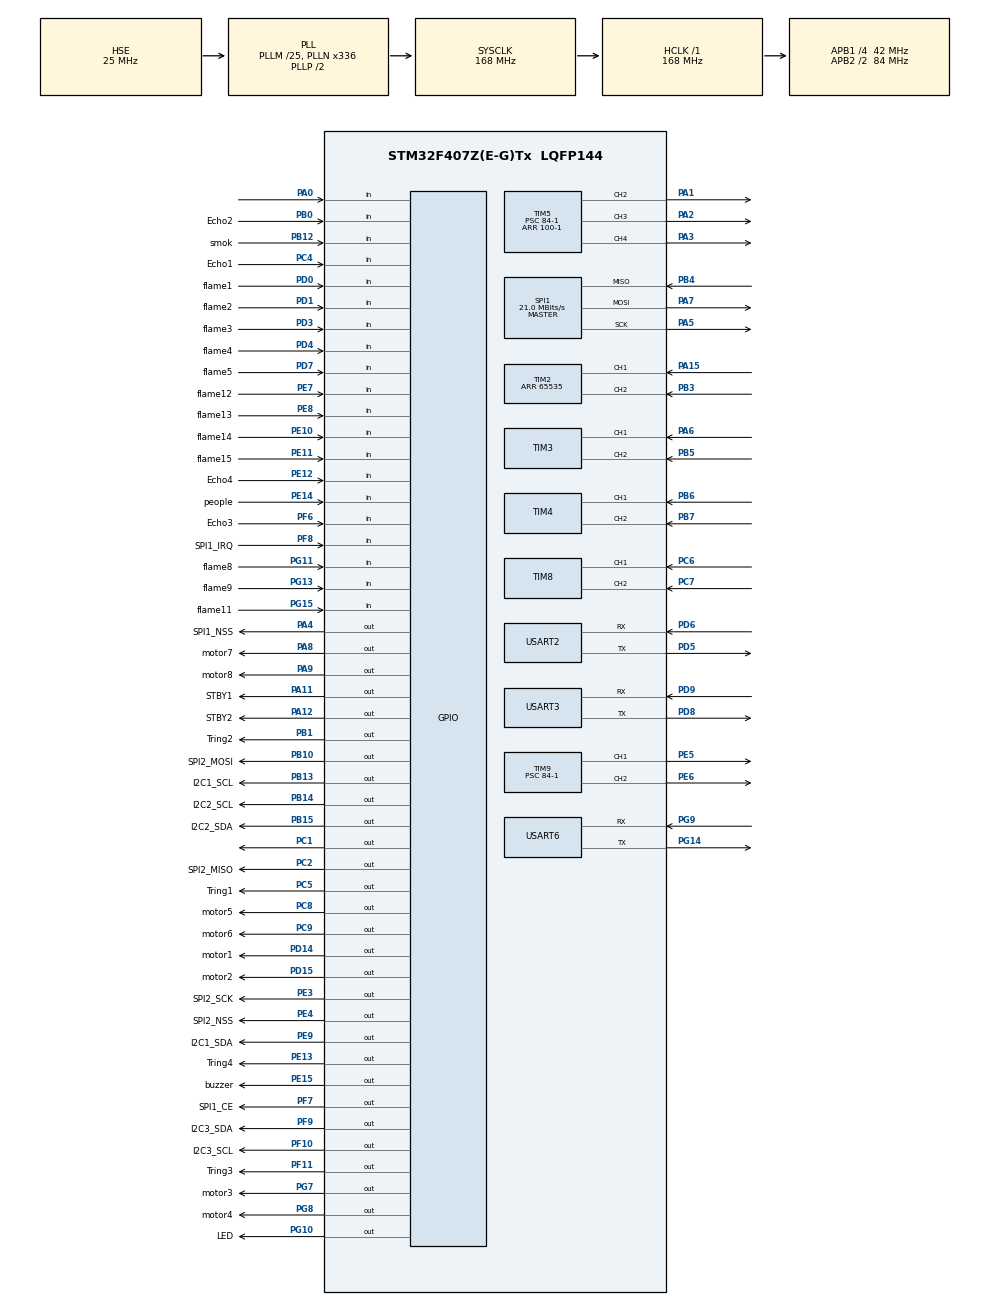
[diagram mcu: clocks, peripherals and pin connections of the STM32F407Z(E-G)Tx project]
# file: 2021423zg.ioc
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Dma.Request0=USART2_RX
Dma.Request1=SPI1_TX
Dma.Request2=USART6_RX
Dma.SPI1_TX.1.Direction=DMA_MEMORY_TO_PERIPH
Dma.SPI1_TX.1.FIFOMode=DMA_FIFOMODE_DISABLE
Dma.SPI1_TX.1.Instance=DMA2_Stream3
Dma.SPI1_TX.1.MemDataAlignment=DMA_MDATAALIGN_BYTE
Dma.SPI1_TX.1.MemInc=DMA_MINC_ENABLE
Dma.SPI1_TX.1.Mode=DMA_CIRCULAR
Dma.SPI1_TX.1.PeriphDataAlignment=DMA_PDATAALIGN_BYTE
Dma.SPI1_TX.1.PeriphInc=DMA_PINC_DISABLE
Dma.SPI1_TX.1.Priority=DMA_PRIORITY_LOW
Dma.USART2_RX.0.Direction=DMA_PERIPH_TO_MEMORY
Dma.USART2_RX.0.FIFOMode=DMA_FIFOMODE_DISABLE
Dma.USART2_RX.0.Instance=DMA1_Stream5
Dma.USART2_RX.0.MemDataAlignment=DMA_MDATAALIGN_BYTE
Dma.USART2_RX.0.MemInc=DMA_MINC_ENABLE
Dma.USART2_RX.0.Mode=DMA_CIRCULAR
Dma.USART2_RX.0.PeriphDataAlignment=DMA_PDATAALIGN_BYTE
Dma.USART2_RX.0.PeriphInc=DMA_PINC_DISABLE
Dma.USART2_RX.0.Priority=DMA_PRIORITY_LOW
Dma.USART6_RX.2.Direction=DMA_PERIPH_TO_MEMORY
Dma.USART6_RX.2.FIFOMode=DMA_FIFOMODE_DISABLE
Dma.USART6_RX.2.Instance=DMA2_Stream1
Dma.USART6_RX.2.MemDataAlignment=DMA_MDATAALIGN_BYTE
Dma.USART6_RX.2.MemInc=DMA_MINC_ENABLE
Dma.USART6_RX.2.Mode=DMA_CIRCULAR
Dma.USART6_RX.2.PeriphDataAlignment=DMA_PDATAALIGN_BYTE
Dma.USART6_RX.2.PeriphInc=DMA_PINC_DISABLE
Dma.USART6_RX.2.Priority=DMA_PRIORITY_LOW
Mcu.Family=STM32F4
Mcu.Name=STM32F407Z(E-G)Tx
Mcu.Package=LQFP144
NVIC.DMA1_Stream5_IRQn=true\:0\:0\:false\:false\:true\:false\:true
NVIC.DMA2_Stream1_IRQn=true\:0\:0\:false\:false\:true\:false\:true
NVIC.DMA2_Stream3_IRQn=true\:0\:0\:false\:false\:true\:false\:true
NVIC.PriorityGroup=NVIC_PRIORITYGROUP_4
NVIC.TIM1_UP_TIM10_IRQn=true\:0\:0\:false\:false\:true\:true\:true
NVIC.TIM8_UP_TIM13_IRQn=true\:0\:0\:false\:false\:true\:false\:true
NVIC.USART3_IRQn=true\:4\:0\:true\:false\:true\:true\:true
PA0-WKUP.Signal=GPIO_Input
PA1.Signal=S_TIM5_CH2
PA11.GPIO_Label=STBY1
PA11.Signal=GPIO_Output
PA12.GPIO_Label=STBY2
PA12.Signal=GPIO_Output
PA13.Mode=Serial_Wire
PA13.Signal=SYS_JTMS-SWDIO
PA14.Mode=Serial_Wire
PA14.Signal=SYS_JTCK-SWCLK
PA15.Signal=S_TIM2_CH1_ETR
PA2.Signal=S_TIM5_CH3
PA3.Signal=S_TIM5_CH4
PA4.GPIO_Label=SPI1_NSS
PA4.GPIO_PuPd=GPIO_PULLUP
PA4.GPIO_Speed=GPIO_SPEED_FREQ_HIGH
PA4.Signal=GPIO_Output
PA5.Mode=Full_Duplex_Master
PA5.Signal=SPI1_SCK
PA6.Signal=S_TIM3_CH1
PA7.Mode=Full_Duplex_Master
PA7.Signal=SPI1_MOSI
PA8.GPIO_Label=motor7
PA8.Signal=GPIO_Output
PA9.GPIO_Label=motor8
PA9.Signal=GPIO_Output
PB0.GPIO_Label=Echo2
PB0.GPIO_Mode=GPIO_MODE_INPUT
PB0.GPIO_PuPd=GPIO_NOPULL
PB0.Signal=GPIO_Input
PB1.GPIO_Label=Tring2
PB1.GPIO_ModeDefaultOutputPP=GPIO_MODE_OUTPUT_PP
PB1.GPIO_PuPd=GPIO_NOPULL
PB1.GPIO_Speed=GPIO_SPEED_FREQ_LOW
PB1.PinState=GPIO_PIN_RESET
PB1.Signal=GPIO_Output
PB10.GPIO_Label=SPI2_MOSI
PB10.Signal=GPIO_Output
PB12.GPIO_Label=smok
PB12.GPIO_PuPd=GPIO_PULLUP
PB12.Signal=GPIO_Input
PB13.GPIO_Label=I2C1_SCL
PB13.Signal=GPIO_Output
PB14.GPIO_Label=I2C2_SCL
PB14.Signal=GPIO_Output
PB15.GPIO_Label=I2C2_SDA
PB15.Signal=GPIO_Output
PB3.Signal=S_TIM2_CH2
PB4.Mode=Full_Duplex_Master
PB4.Signal=SPI1_MISO
PB5.Signal=S_TIM3_CH2
PB6.Signal=S_TIM4_CH1
PB7.Signal=S_TIM4_CH2
PC1.Signal=GPIO_Output
PC14-OSC32_IN.Mode=LSE-External-Oscillator
PC14-OSC32_IN.Signal=RCC_OSC32_IN
PC15-OSC32_OUT.Mode=LSE-External-Oscillator
PC15-OSC32_OUT.Signal=RCC_OSC32_OUT
PC2.GPIO_Label=SPI2_MISO
PC2.Signal=GPIO_Output
PC4.GPIO_Label=Echo1
PC4.GPIO_Mode=GPIO_MODE_INPUT
PC4.GPIO_PuPd=GPIO_NOPULL
PC4.Signal=GPIO_Input
PC5.GPIO_Label=Tring1
PC5.GPIO_ModeDefaultOutputPP=GPIO_MODE_OUTPUT_PP
PC5.GPIO_PuPd=GPIO_NOPULL
PC5.GPIO_Speed=GPIO_SPEED_FREQ_LOW
PC5.PinState=GPIO_PIN_RESET
PC5.Signal=GPIO_Output
PC6.Signal=S_TIM8_CH1
PC7.Signal=S_TIM8_CH2
PC8.GPIO_Label=motor5
PC8.GPIO_ModeDefaultOutputPP=GPIO_MODE_OUTPUT_PP
PC8.GPIO_PuPd=GPIO_NOPULL
PC8.GPIO_Speed=GPIO_SPEED_FREQ_LOW
PC8.PinState=GPIO_PIN_RESET
PC8.Signal=GPIO_Output
PC9.GPIO_Label=motor6
PC9.GPIO_ModeDefaultOutputPP=GPIO_MODE_OUTPUT_PP
PC9.GPIO_PuPd=GPIO_NOPULL
PC9.GPIO_Speed=GPIO_SPEED_FREQ_LOW
PC9.PinState=GPIO_PIN_RESET
PC9.Signal=GPIO_Output
PD0.GPIO_Label=flame1
PD0.GPIO_PuPd=GPIO_PULLDOWN
PD0.Signal=GPIO_Input
PD1.GPIO_Label=flame2
PD1.GPIO_PuPd=GPIO_PULLDOWN
PD1.Signal=GPIO_Input
PD14.GPIO_Label=motor1
PD14.Signal=GPIO_Output
PD15.GPIO_Label=motor2
PD15.GPIO_ModeDefaultOutputPP=GPIO_MODE_OUTPUT_PP
PD15.GPIO_PuPd=GPIO_NOPULL
PD15.GPIO_Speed=GPIO_SPEED_FREQ_LOW
PD15.PinState=GPIO_PIN_RESET
PD15.Signal=GPIO_Output
PD3.GPIO_Label=flame3
PD3.GPIO_PuPd=GPIO_PULLDOWN
PD3.Signal=GPIO_Input
PD4.GPIO_Label=flame4
PD4.GPIO_PuPd=GPIO_PULLDOWN
PD4.Signal=GPIO_Input
PD5.Mode=Asynchronous
PD5.Signal=USART2_TX
PD6.Mode=Asynchronous
PD6.Signal=USART2_RX
PD7.GPIO_Label=flame5
PD7.GPIO_PuPd=GPIO_PULLDOWN
PD7.Signal=GPIO_Input
PD8.Mode=Asynchronous
PD8.Signal=USART3_TX
PD9.Mode=Asynchronous
PD9.Signal=USART3_RX
PE10.GPIO_Label=flame14
PE10.GPIO_PuPd=GPIO_PULLDOWN
PE10.Signal=GPIO_Input
PE11.GPIO_Label=flame15
PE11.GPIO_PuPd=GPIO_PULLDOWN
PE11.Signal=GPIO_Input
PE12.GPIO_Label=Echo4
PE12.Signal=GPIO_Input
PE13.GPIO_Label=Tring4
PE13.Signal=GPIO_Output
PE14.GPIO_Label=people
PE14.Signal=GPIO_Input
PE15.GPIO_Label=buzzer
PE15.GPIO_PuPd=GPIO_PULLDOWN
PE15.PinState=GPIO_PIN_RESET
PE15.Signal=GPIO_Output
PE3.GPIO_Label=SPI2_SCK
PE3.Signal=GPIO_Output
PE4.GPIO_Label=SPI2_NSS
PE4.Signal=GPIO_Output
PE5.Signal=S_TIM9_CH1
PE6.Signal=S_TIM9_CH2
PE7.GPIO_Label=flame12
PE7.GPIO_PuPd=GPIO_PULLDOWN
PE7.Signal=GPIO_Input
PE8.GPIO_Label=flame13
PE8.GPIO_PuPd=GPIO_PULLDOWN
PE8.Signal=GPIO_Input
PE9.GPIO_Label=I2C1_SDA
PE9.Signal=GPIO_Output
PF10.GPIO_Label=I2C3_SCL
PF10.Signal=GPIO_Output
PF11.GPIO_Label=Tring3
PF11.GPIO_ModeDefaultOutputPP=GPIO_MODE_OUTPUT_PP
PF11.GPIO_PuPd=GPIO_NOPULL
PF11.GPIO_Speed=GPIO_SPEED_FREQ_LOW
PF11.PinState=GPIO_PIN_RESET
PF11.Signal=GPIO_Output
PF6.GPIO_Label=Echo3
PF6.Signal=GPIO_Input
PF7.GPIO_Label=SPI1_CE
PF7.GPIO_PuPd=GPIO_PULLUP
PF7.GPIO_Speed=GPIO_SPEED_FREQ_LOW
PF7.PinState=GPIO_PIN_SET
PF7.Signal=GPIO_Output
PF8.GPIO_Label=SPI1_IRQ
PF8.GPIO_PuPd=GPIO_PULLUP
PF8.Signal=GPIO_Input
PF9.GPIO_Label=I2C3_SDA
PF9.Signal=GPIO_Output
PG10.GPIO_Label=LED
PG10.GPIO_PuPd=GPIO_PULLDOWN
PG10.Signal=GPIO_Output
PG11.GPIO_Label=flame8
PG11.GPIO_PuPd=GPIO_PULLDOWN
PG11.Signal=GPIO_Input
PG13.GPIO_Label=flame9
PG13.GPIO_PuPd=GPIO_PULLDOWN
PG13.Signal=GPIO_Input
PG14.Mode=Asynchronous
PG14.Signal=USART6_TX
PG15.GPIO_Label=flame11
PG15.GPIO_PuPd=GPIO_PULLDOWN
PG15.Signal=GPIO_Input
PG7.GPIO_Label=motor3
PG7.GPIO_ModeDefaultOutputPP=GPIO_MODE_OUTPUT_PP
PG7.GPIO_PuPd=GPIO_NOPULL
PG7.GPIO_Speed=GPIO_SPEED_FREQ_LOW
PG7.PinState=GPIO_PIN_RESET
PG7.Signal=GPIO_Output
PG8.GPIO_Label=motor4
PG8.GPIO_ModeDefaultOutputPP=GPIO_MODE_OUTPUT_PP
PG8.GPIO_PuPd=GPIO_NOPULL
PG8.GPIO_Speed=GPIO_SPEED_FREQ_LOW
PG8.PinState=GPIO_PIN_RESET
PG8.Signal=GPIO_Output
PG9.Mode=Asynchronous
PG9.Signal=USART6_RX
PH0-OSC_IN.Mode=HSE-External-Oscillator
PH0-OSC_IN.Signal=RCC_OSC_IN
PH1-OSC_OUT.Mode=HSE-External-Oscillator
PH1-OSC_OUT.Signal=RCC_OSC_OUT
ProjectManager.HeapSize=0x200
ProjectManager.StackSize=0x400
ProjectManager.TargetToolchain=STM32CubeIDE
RCC.48MHZClocksFreq_Value=84000000
RCC.AHBFreq_Value=168000000
RCC.APB1CLKDivider=RCC_HCLK_DIV4
RCC.APB1Freq_Value=42000000
RCC.APB1TimFreq_Value=84000000
RCC.APB2CLKDivider=RCC_HCLK_DIV2
RCC.APB2Freq_Value=84000000
RCC.APB2TimFreq_Value=168000000
RCC.CortexFreq_Value=168000000
RCC.HCLKFreq_Value=168000000
RCC.HSE_VALUE=25000000
RCC.HSI_VALUE=16000000
RCC.PLLM=25
RCC.PLLN=336
RCC.PLLSourceVirtual=RCC_PLLSOURCE_HSE
RCC.SYSCLKFreq_VALUE=168000000
RCC.SYSCLKSource=RCC_SYSCLKSOURCE_PLLCLK
RCC.VCOOutputFreq_Value=336000000
SH.S_TIM2_CH1_ETR.0=TIM2_CH1,Encoder_Interface
SH.S_TIM2_CH2.0=TIM2_CH2,Encoder_Interface
SH.S_TIM3_CH1.0=TIM3_CH1,Encoder_Interface
SH.S_TIM3_CH2.0=TIM3_CH2,Encoder_Interface
SH.S_TIM4_CH1.0=TIM4_CH1,Encoder_Interface
SH.S_TIM4_CH2.0=TIM4_CH2,Encoder_Interface
SH.S_TIM5_CH2.0=TIM5_CH2,PWM Generation2 CH2
SH.S_TIM5_CH3.0=TIM5_CH3,PWM Generation3 CH3
SH.S_TIM5_CH4.0=TIM5_CH4,PWM Generation4 CH4
SH.S_TIM8_CH1.0=TIM8_CH1,Encoder_Interface
SH.S_TIM8_CH2.0=TIM8_CH2,Encoder_Interface
SH.S_TIM9_CH1.0=TIM9_CH1,PWM Generation1 CH1
SH.S_TIM9_CH2.0=TIM9_CH2,PWM Generation2 CH2
SPI1.BaudRatePrescaler=SPI_BAUDRATEPRESCALER_4
SPI1.CalculateBaudRate=21.0 MBits/s
SPI1.Direction=SPI_DIRECTION_2LINES
SPI1.Mode=SPI_MODE_MASTER
SPI1.VirtualType=VM_MASTER
TIM1.AutoReloadPreload=TIM_AUTORELOAD_PRELOAD_ENABLE
TIM1.Period=1000-1
TIM1.Prescaler=168-1
TIM10.AutoReloadPreload=TIM_AUTORELOAD_PRELOAD_ENABLE
TIM10.Period=10000-1
TIM10.Prescaler=16800-1
TIM11.AutoReloadPreload=TIM_AUTORELOAD_PRELOAD_ENABLE
TIM11.Period=50000-1
TIM11.Prescaler=16800-1
TIM2.AutoReloadPreload=TIM_AUTORELOAD_PRELOAD_ENABLE
TIM2.EncoderMode=TIM_ENCODERMODE_TI12
TIM2.Period=65535
TIM3.AutoReloadPreload=TIM_AUTORELOAD_PRELOAD_ENABLE
TIM3.EncoderMode=TIM_ENCODERMODE_TI12
TIM3.IC1Filter=10
TIM3.IC2Filter=10
TIM4.AutoReloadPreload=TIM_AUTORELOAD_PRELOAD_ENABLE
TIM4.EncoderMode=TIM_ENCODERMODE_TI12
TIM5.AutoReloadPreload=TIM_AUTORELOAD_PRELOAD_ENABLE
TIM5.Channel-PWM\ Generation2\ CH2=TIM_CHANNEL_2
TIM5.Channel-PWM\ Generation3\ CH3=TIM_CHANNEL_3
TIM5.Channel-PWM\ Generation4\ CH4=TIM_CHANNEL_4
TIM5.OCMode_PWM-PWM\ Generation4\ CH4=TIM_OCMODE_PWM1
TIM5.Period=100-1
TIM5.Prescaler=84-1
TIM6.AutoReloadPreload=TIM_AUTORELOAD_PRELOAD_ENABLE
TIM6.Period=50000-1
TIM6.Prescaler=84-1
TIM7.AutoReloadPreload=TIM_AUTORELOAD_PRELOAD_ENABLE
TIM7.Period=10000-1
TIM7.Prescaler=8400-1
TIM7.TIM_MasterOutputTrigger=TIM_TRGO_RESET
TIM8.AutoReloadPreload=TIM_AUTORELOAD_PRELOAD_ENABLE
TIM8.EncoderMode=TIM_ENCODERMODE_TI12
TIM8.IC1Filter=10
TIM8.IC2Filter=10
TIM9.AutoReloadPreload=TIM_AUTORELOAD_PRELOAD_ENABLE
TIM9.Channel-PWM\ Generation1\ CH1=TIM_CHANNEL_1
TIM9.Channel-PWM\ Generation2\ CH2=TIM_CHANNEL_2
TIM9.OCMode_PWM-PWM\ Generation2\ CH2=TIM_OCMODE_PWM1
TIM9.Period=100-1
TIM9.Prescaler=84-1
USART2.VirtualMode=VM_ASYNC
USART3.VirtualMode=VM_ASYNC
USART6.VirtualMode=VM_ASYNC
VP_TIM10_VS_ClockSourceINT.Mode=Enable_Timer
VP_TIM11_VS_ClockSourceINT.Mode=Enable_Timer
VP_TIM1_VS_ClockSourceINT.Mode=Internal
VP_TIM5_VS_ClockSourceINT.Mode=Internal
VP_TIM6_VS_ClockSourceINT.Mode=Enable_Timer
VP_TIM7_VS_ClockSourceINT.Mode=Enable_Timer
VP_TIM9_VS_ClockSourceINT.Mode=Internal
board=custom

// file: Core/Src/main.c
/* USER CODE BEGIN Header */
/**
  ******************************************************************************
  * @file           : main.c
  * @brief          : Main program body
  ******************************************************************************
  * @attention
  *
  * <h2><center>&copy; Copyright (c) 2021 STMicroelectronics.
  * All rights reserved.</center></h2>
  *
  * This software component is licensed by ST under BSD 3-Clause license,
  * the "License"; You may not use this file except in compliance with the
  * License. You may obtain a copy of the License at:
  *                        opensource.org/licenses/BSD-3-Clause
  *
  ******************************************************************************
  */
/* USER CODE END Header */
#include "main.h"
#include "dma.h"
#include "spi.h"
#include "tim.h"
#include "usart.h"
#include "gpio.h"

/* USER CODE BEGIN Includes */

#include "delay.h"
#include "start.h"
#include "math.h"
#include "motor_l1.h"
#include "motor_l2.h"
#include "motor_r1.h"
#include "motor_r2.h"
#include "communication.h"
#include "ultrasonic.h"
#include "people.h"
#include "flame.h"
#include "smok.h"
#include "buzzer.h"
#include "mbotLinuxUsart.h"

/* USER CODE END Includes */

/* USER CODE BEGIN PTD */

float leftvollinearvelocity_pre=0;
float rightvollinearvelocity_pre=0;
int leftvollinearvelocity_set=0;
int rightvollinearvelocity_set=0;
unsigned char p_crtlFlag=0;

float setpoint[4]={0};
unsigned char date[30];
int motor=0;
int ultrasonic=0;
int sensor=0;
int send=0;
int receive=0;
int spi=0;
unsigned char date_t[8]={0x56,0xaa,0,0,0,0,0,0};

//测试发�?�变�????????????
short testSend1   =5000;
short testSend2   =2000;
short testSend3   =1000;
unsigned char testSend4 = 0x05;

//测试接收变量
int testRece1     =0;
int testRece2     =0;
unsigned char testRece3 = 0x00;

/* USER CODE END PTD */

void SystemClock_Config(void);

int main(void)
{

  /* MCU Configuration--------------------------------------------------------*/

  /* Reset of all peripherals, Initializes the Flash interface and the Systick. */
  HAL_Init();

  /* Configure the system clock */
  SystemClock_Config();

  /* Initialize all configured peripherals */
  MX_GPIO_Init();
  MX_DMA_Init();
  MX_TIM3_Init();
  MX_TIM4_Init();
  MX_TIM2_Init();
  MX_TIM9_Init();
  MX_TIM5_Init();
  MX_TIM8_Init();
  MX_TIM6_Init();
  MX_SPI1_Init();
  MX_USART2_UART_Init();
  MX_USART3_UART_Init();
  MX_TIM1_Init();
  MX_TIM7_Init();
  MX_TIM10_Init();
  MX_TIM11_Init();
  MX_USART6_UART_Init();
  /* USER CODE BEGIN 2 */

  /*
  //====================================串口中断服务程序=================================================
  void HAL_UART_RxCpltCallback()
  {
  	if(HAL_UART_GetState(&huart2) == HAL_UART_STATE_BUSY_RX)
   	 {
  		// USART_ClearITPendingBit(USART1,USART_IT_RXNE);//首先清除中断标志�????????????
  		 //从ROS接收到的数据，存放到下面三个变量�????????????
  		 usartReceiveOneData(&testRece1,&testRece2,&testRece3);
  	 }
  }
  __HAL_UART_ENABLE_IT(&huart2, UART_IT_ERR);

*/
//int rx_buffer[]={0};
//HAL_UART_Receive_DMA(&huart2,rx_buffer,11);
 //  电机控制程序
 //PWM，编码器，芯片使�????????????????????????????????????????????
  motor_start();

   //读取给定速度并转�????????????????????????????????????????????
  //readsetpoint(0.1,0,setpoint);
   __HAL_SPI_ENABLE(&hspi1);
	HAL_GPIO_WritePin(SPI1_CE_GPIO_Port,SPI1_CE_Pin,1);
//打开定时器中
  HAL_TIM_Base_Start_IT(&htim1);

  /* USER CODE END 2 */

  /* Infinite loop */
  while (1)
  {

  }
}

void SystemClock_Config(void)
{
  RCC_OscInitTypeDef RCC_OscInitStruct = {0};
  RCC_ClkInitTypeDef RCC_ClkInitStruct = {0};

  /** Configure the main internal regulator output voltage
  */
  __HAL_RCC_PWR_CLK_ENABLE();
  __HAL_PWR_VOLTAGESCALING_CONFIG(PWR_REGULATOR_VOLTAGE_SCALE1);
  /** Initializes the RCC Oscillators according to the specified parameters
  * in the RCC_OscInitTypeDef structure.
  */
  RCC_OscInitStruct.OscillatorType = RCC_OSCILLATORTYPE_HSE;
  RCC_OscInitStruct.HSEState = RCC_HSE_ON;
  RCC_OscInitStruct.PLL.PLLState = RCC_PLL_ON;
  RCC_OscInitStruct.PLL.PLLSource = RCC_PLLSOURCE_HSE;
  RCC_OscInitStruct.PLL.PLLM = 25;
  RCC_OscInitStruct.PLL.PLLN = 336;
  RCC_OscInitStruct.PLL.PLLP = RCC_PLLP_DIV2;
  RCC_OscInitStruct.PLL.PLLQ = 4;
  if (HAL_RCC_OscConfig(&RCC_OscInitStruct) != HAL_OK)
  {
    Error_Handler();
  }
  /** Initializes the CPU, AHB and APB buses clocks
  */
  RCC_ClkInitStruct.ClockType = RCC_CLOCKTYPE_HCLK|RCC_CLOCKTYPE_SYSCLK
                              |RCC_CLOCKTYPE_PCLK1|RCC_CLOCKTYPE_PCLK2;
  RCC_ClkInitStruct.SYSCLKSource = RCC_SYSCLKSOURCE_PLLCLK;
  RCC_ClkInitStruct.AHBCLKDivider = RCC_SYSCLK_DIV1;
  RCC_ClkInitStruct.APB1CLKDivider = RCC_HCLK_DIV4;
  RCC_ClkInitStruct.APB2CLKDivider = RCC_HCLK_DIV2;

  if (HAL_RCC_ClockConfig(&RCC_ClkInitStruct, FLASH_LATENCY_5) != HAL_OK)
  {
    Error_Handler();
  }
}

/* USER CODE BEGIN 4 */

void HAL_TIM_PeriodElapsedCallback(TIM_HandleTypeDef *htim)
{
	if (htim==&htim1)//判断是否威定时器7中断
	{
		motor++;
		ultrasonic++;
		sensor++;
		send++;
		receive++;
	if(motor==200)
		{
	//	leftvollinearvelocity_set=200;
		//rightvollinearvelocity_set=200;
		float v[4]={0};//小车实际线�?�度清零
		float angular[4]={0};//计算小车转动角度清零
		//控制小车前进或后�???????????????????????????????????????????
		// readsetpoint(leftvollinearvelocity_,rightvollinearvelocity_set,setpoint);
	    go_or_back_L_1((float)leftvollinearvelocity_set);
		go_or_back_L_2((float)leftvollinearvelocity_set);
		go_or_back_R_1((float)rightvollinearvelocity_set);
		go_or_back_R_2((float)rightvollinearvelocity_set);
		//测出小车行驶速度
		v[0]= contol_L_1((float)leftvollinearvelocity_set,(float)rightvollinearvelocity_set,angular);
		v[1]= contol_L_2((float)leftvollinearvelocity_set,(float)rightvollinearvelocity_set,angular);
		v[2]= contol_R_1((float)rightvollinearvelocity_set,(float)leftvollinearvelocity_set,angular);
		v[3]= contol_R_2((float)rightvollinearvelocity_set,(float)leftvollinearvelocity_set,angular);
		date[12]=(v[0]+v[1]+v[2]+v[3])/4*1000;//计算小车4个轮子平均�?�度
		date[13]=(angular[0]+angular[1]+angular[2]+angular[3])/4*1000;//计算小车4个轮子平均转角度
		leftvollinearvelocity_pre=(v[1]+v[1])/2*1000;
		rightvollinearvelocity_pre=(v[2]+v[3])/2*1000;
		motor=0;
		__HAL_TIM_SET_COMPARE(&htim5,TIM_CHANNEL_3,20);//通过pwm控制电机速度
		__HAL_TIM_SET_COMPARE(&htim5,TIM_CHANNEL_4,20);//通过pwm控制电机速度
		__HAL_TIM_SET_COMPARE(&htim9,TIM_CHANNEL_1,20);//通过pwm控制电机速度
		__HAL_TIM_SET_COMPARE(&htim9,TIM_CHANNEL_2,20);//通过pwm控制电机速度
		date_t[7]=(leftvollinearvelocity_pre+rightvollinearvelocity_pre)/2;

		}
		/*if(ultrasonic==300)
			{
			float t1,t2,t3,t4=0;
			HAL_TIM_Encoder_Stop(&htim3,TIM_CHANNEL_ALL);
			HAL_TIM_Encoder_Stop(&htim4,TIM_CHANNEL_ALL);
			HAL_TIM_Encoder_Stop(&htim2,TIM_CHANNEL_ALL);
			HAL_TIM_Encoder_Stop(&htim8,TIM_CHANNEL_ALL);
			HAL_TIM_Base_Start(&htim7);//启动定时�????????????????????7
			htim7.Instance->CNT = 0;//定时�????????????????????6计数器清0
			Ultrasonic1(date);
			 t1=htim7.Instance->CNT;
			//Ultrasonic2(date);
			 t2=htim7.Instance->CNT;
			Ultrasonic3(date);
			 t3=htim7.Instance->CNT;
			Ultrasonic4(date);
			ultrasonic=0;
			 t4=htim7.Instance->CNT;
			 date[7]=date[7]-(t4-t1)*0.0001*date[12];
			 date[8]=date[8]-(t4-t2)*0.0001*date[12];
			 date[9]=date[9]-(t4-t3)*0.0001*date[12];
			 HAL_TIM_Base_Stop(&htim7);//启动定时�????????????????????7
			 if(date[7]<20||date[8]<20||date[9]<20||date[10]<20)
			{
				HAL_GPIO_WritePin(buzzer_GPIO_Port, buzzer_Pin, 1);
				HAL_GPIO_WritePin(LED_GPIO_Port, LED_Pin, 1);
			}
			else
			{
				HAL_GPIO_WritePin(buzzer_GPIO_Port, buzzer_Pin, 0);
				HAL_GPIO_WritePin(LED_GPIO_Port, LED_Pin, 0);
			}
			HAL_TIM_Encoder_Start(&htim3,TIM_CHANNEL_ALL);
			HAL_TIM_Encoder_Start(&htim4,TIM_CHANNEL_ALL);
			HAL_TIM_Encoder_Start(&htim2,TIM_CHANNEL_ALL);
			 HAL_TIM_Encoder_Start(&htim8,TIM_CHANNEL_ALL);
			}*/
		if (sensor==1000)
		{
			HAL_TIM_Encoder_Stop(&htim3,TIM_CHANNEL_ALL);
			HAL_TIM_Encoder_Stop(&htim4,TIM_CHANNEL_ALL);
			HAL_TIM_Encoder_Stop(&htim2,TIM_CHANNEL_ALL);
			HAL_TIM_Encoder_Stop(&htim8,TIM_CHANNEL_ALL);
			SMOK_PUT(date);
			FLAME_A_PUT(date);
			FLAME_B_PUT(date);
			FLAME_C_PUT(date);
			PEOPLE_PUT(date);
			date_t[2]=date[1];
			date_t[3]=date[2];
			date_t[4]=date[3];
			date_t[5]=date[4];
			 if(date[1]||date[2]||date[3]||date[4]==1)
				{
					HAL_GPIO_WritePin(buzzer_GPIO_Port, buzzer_Pin, 1);
					HAL_GPIO_WritePin(LED_GPIO_Port, LED_Pin, 1);
				}
			else
				{
					HAL_GPIO_WritePin(buzzer_GPIO_Port, buzzer_Pin, 0);
					HAL_GPIO_WritePin(LED_GPIO_Port, LED_Pin, 0);
				}
			sensor=0;
		HAL_TIM_Encoder_Start(&htim3,TIM_CHANNEL_ALL);
		HAL_TIM_Encoder_Start(&htim4,TIM_CHANNEL_ALL);
		HAL_TIM_Encoder_Start(&htim2,TIM_CHANNEL_ALL);
		HAL_TIM_Encoder_Start(&htim8,TIM_CHANNEL_ALL);
	}
		if (send==100)
	{
			HAL_TIM_Encoder_Stop(&htim3,TIM_CHANNEL_ALL);
			HAL_TIM_Encoder_Stop(&htim4,TIM_CHANNEL_ALL);
			HAL_TIM_Encoder_Stop(&htim2,TIM_CHANNEL_ALL);
			HAL_TIM_Encoder_Stop(&htim8,TIM_CHANNEL_ALL);
			usartSendData(leftvollinearvelocity_pre,rightvollinearvelocity_pre,0,0);
			USART_Send_String(date_t,8);
			HAL_TIM_Encoder_Start(&htim3,TIM_CHANNEL_ALL);
			HAL_TIM_Encoder_Start(&htim4,TIM_CHANNEL_ALL);
			HAL_TIM_Encoder_Start(&htim2,TIM_CHANNEL_ALL);
			HAL_TIM_Encoder_Start(&htim8,TIM_CHANNEL_ALL);
			send=0;
	}

	if (receive==50)
			{
					HAL_TIM_Encoder_Stop(&htim3,TIM_CHANNEL_ALL);
					HAL_TIM_Encoder_Stop(&htim4,TIM_CHANNEL_ALL);
					HAL_TIM_Encoder_Stop(&htim2,TIM_CHANNEL_ALL);
					HAL_TIM_Encoder_Stop(&htim8,TIM_CHANNEL_ALL);
					//HAL_UART_DMAResume(&huart2);
					usartReceiveOneData(&leftvollinearvelocity_set,&rightvollinearvelocity_set,&p_crtlFlag);
					//HAL_UART_DMAPause(&huart2);
					HAL_TIM_Encoder_Start(&htim3,TIM_CHANNEL_ALL);
					HAL_TIM_Encoder_Start(&htim4,TIM_CHANNEL_ALL);
					HAL_TIM_Encoder_Start(&htim2,TIM_CHANNEL_ALL);
					HAL_TIM_Encoder_Start(&htim8,TIM_CHANNEL_ALL);
					receive=0;
			}
	}
}

/* USER CODE END 4 */

void Error_Handler(void)
{
}

/************************ (C) COPYRIGHT STMicroelectronics *****END OF FILE****/
